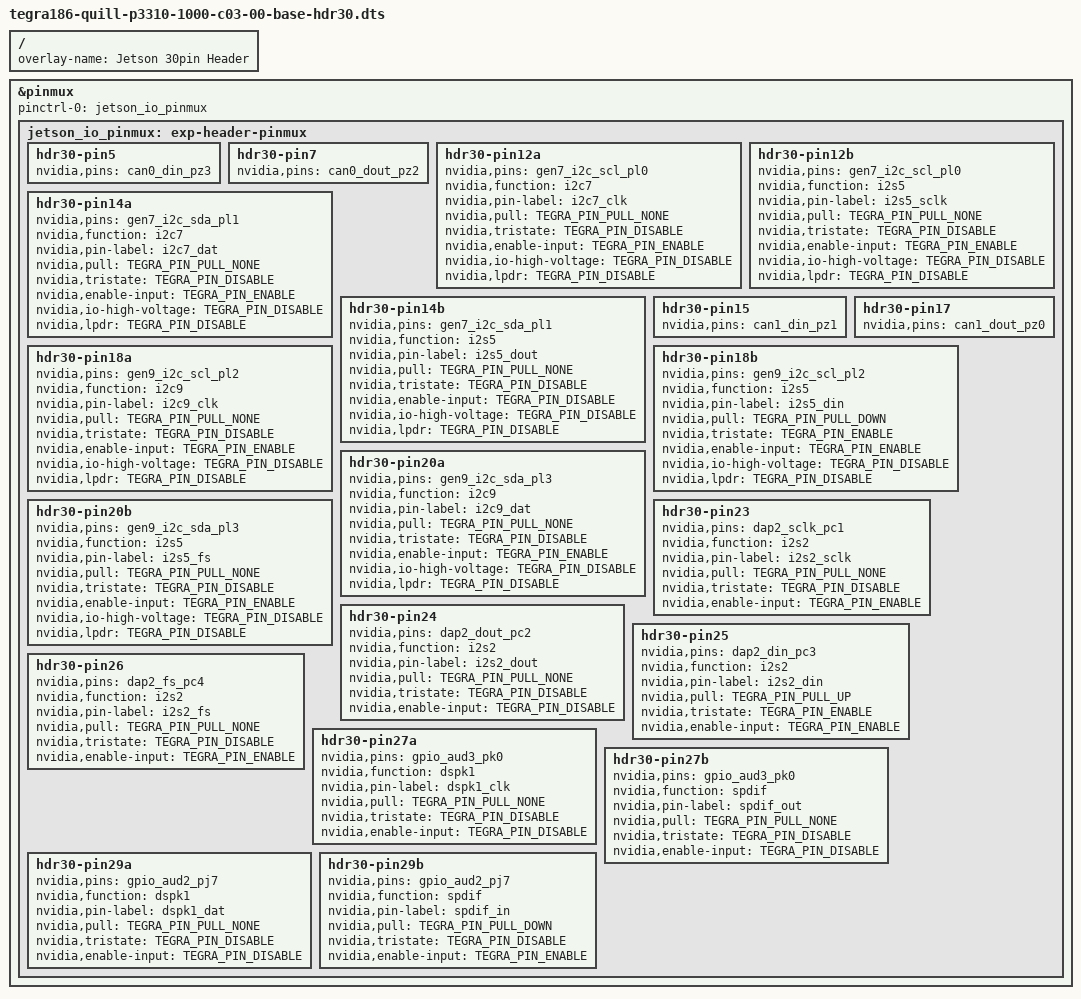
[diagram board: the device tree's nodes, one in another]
/*
 * Copyright (c) 2021, NVIDIA CORPORATION.  All rights reserved.
 *
 * This program is free software; you can redistribute it and/or modify it
 * under the terms and conditions of the GNU General Public License,
 * version 2, as published by the Free Software Foundation.
 *
 * This program is distributed in the hope it will be useful, but WITHOUT
 * ANY WARRANTY; without even the implied warranty of MERCHANTABILITY or
 * FITNESS FOR A PARTICULAR PURPOSE.  See the GNU General Public License for
 * more details.
 *
 * You should have received a copy of the GNU General Public License
 * along with this program.  If not, see <http://www.gnu.org/licenses/>.
 */

/*
 * Device-tree overlay for tegra186-quill-p3310-1000-c03-00-base
 * 30-pin Expansion Header.
 */

/dts-v1/;
/plugin/;

#include <dt-bindings/pinctrl/pinctrl-tegra.h>
#include <dt-common/jetson/tegra186-quill-p3310-1000-c03-00-base.h>

/ {
	overlay-name = "Jetson 30pin Header";
	compatible = JETSON_COMPATIBLE;

	fragment@0 {
		target = <&pinmux>;
		__overlay__ {
			pinctrl-names = "default";
			pinctrl-0 = <&jetson_io_pinmux>;
			jetson_io_pinmux: exp-header-pinmux {
				hdr30-pin5 {
					nvidia,pins = "can0_din_pz3";
				};
				hdr30-pin7 {
					nvidia,pins = "can0_dout_pz2";
				};
				hdr30-pin12a {
					nvidia,pins = "gen7_i2c_scl_pl0";
					nvidia,function = "i2c7";
					nvidia,pin-label = "i2c7_clk";
					nvidia,pull = <TEGRA_PIN_PULL_NONE>;
					nvidia,tristate = <TEGRA_PIN_DISABLE>;
					nvidia,enable-input = <TEGRA_PIN_ENABLE>;
					nvidia,io-high-voltage = <TEGRA_PIN_DISABLE>;
					nvidia,lpdr = <TEGRA_PIN_DISABLE>;
				};
				hdr30-pin12b {
					nvidia,pins = "gen7_i2c_scl_pl0";
					nvidia,function = "i2s5";
					nvidia,pin-label = "i2s5_sclk";
					nvidia,pull = <TEGRA_PIN_PULL_NONE>;
					nvidia,tristate = <TEGRA_PIN_DISABLE>;
					nvidia,enable-input = <TEGRA_PIN_ENABLE>;
					nvidia,io-high-voltage = <TEGRA_PIN_DISABLE>;
					nvidia,lpdr = <TEGRA_PIN_DISABLE>;
				};
				hdr30-pin14a {
					nvidia,pins = "gen7_i2c_sda_pl1";
					nvidia,function = "i2c7";
					nvidia,pin-label = "i2c7_dat";
					nvidia,pull = <TEGRA_PIN_PULL_NONE>;
					nvidia,tristate = <TEGRA_PIN_DISABLE>;
					nvidia,enable-input = <TEGRA_PIN_ENABLE>;
					nvidia,io-high-voltage = <TEGRA_PIN_DISABLE>;
					nvidia,lpdr = <TEGRA_PIN_DISABLE>;
				};
				hdr30-pin14b {
					nvidia,pins = "gen7_i2c_sda_pl1";
					nvidia,function = "i2s5";
					nvidia,pin-label = "i2s5_dout";
					nvidia,pull = <TEGRA_PIN_PULL_NONE>;
					nvidia,tristate = <TEGRA_PIN_DISABLE>;
					nvidia,enable-input = <TEGRA_PIN_DISABLE>;
					nvidia,io-high-voltage = <TEGRA_PIN_DISABLE>;
					nvidia,lpdr = <TEGRA_PIN_DISABLE>;
				};
				hdr30-pin15 {
					nvidia,pins = "can1_din_pz1";
				};
				hdr30-pin17 {
					nvidia,pins = "can1_dout_pz0";
				};
				hdr30-pin18a {
					nvidia,pins = "gen9_i2c_scl_pl2";
					nvidia,function = "i2c9";
					nvidia,pin-label = "i2c9_clk";
					nvidia,pull = <TEGRA_PIN_PULL_NONE>;
					nvidia,tristate = <TEGRA_PIN_DISABLE>;
					nvidia,enable-input = <TEGRA_PIN_ENABLE>;
					nvidia,io-high-voltage = <TEGRA_PIN_DISABLE>;
					nvidia,lpdr = <TEGRA_PIN_DISABLE>;
				};
				hdr30-pin18b {
					nvidia,pins = "gen9_i2c_scl_pl2";
					nvidia,function = "i2s5";
					nvidia,pin-label = "i2s5_din";
					nvidia,pull = <TEGRA_PIN_PULL_DOWN>;
					nvidia,tristate = <TEGRA_PIN_ENABLE>;
					nvidia,enable-input = <TEGRA_PIN_ENABLE>;
					nvidia,io-high-voltage = <TEGRA_PIN_DISABLE>;
					nvidia,lpdr = <TEGRA_PIN_DISABLE>;
				};
				hdr30-pin20a {
					nvidia,pins = "gen9_i2c_sda_pl3";
					nvidia,function = "i2c9";
					nvidia,pin-label = "i2c9_dat";
					nvidia,pull = <TEGRA_PIN_PULL_NONE>;
					nvidia,tristate = <TEGRA_PIN_DISABLE>;
					nvidia,enable-input = <TEGRA_PIN_ENABLE>;
					nvidia,io-high-voltage = <TEGRA_PIN_DISABLE>;
					nvidia,lpdr = <TEGRA_PIN_DISABLE>;
				};
				hdr30-pin20b {
					nvidia,pins = "gen9_i2c_sda_pl3";
					nvidia,function = "i2s5";
					nvidia,pin-label = "i2s5_fs";
					nvidia,pull = <TEGRA_PIN_PULL_NONE>;
					nvidia,tristate = <TEGRA_PIN_DISABLE>;
					nvidia,enable-input = <TEGRA_PIN_ENABLE>;
					nvidia,io-high-voltage = <TEGRA_PIN_DISABLE>;
					nvidia,lpdr = <TEGRA_PIN_DISABLE>;
				};
				hdr30-pin23 {
					nvidia,pins = "dap2_sclk_pc1";
					nvidia,function = "i2s2";
					nvidia,pin-label = "i2s2_sclk";
					nvidia,pull = <TEGRA_PIN_PULL_NONE>;
					nvidia,tristate = <TEGRA_PIN_DISABLE>;
					nvidia,enable-input = <TEGRA_PIN_ENABLE>;
				};
				hdr30-pin24 {
					nvidia,pins = "dap2_dout_pc2";
					nvidia,function = "i2s2";
					nvidia,pin-label = "i2s2_dout";
					nvidia,pull = <TEGRA_PIN_PULL_NONE>;
					nvidia,tristate = <TEGRA_PIN_DISABLE>;
					nvidia,enable-input = <TEGRA_PIN_DISABLE>;
				};
				hdr30-pin25 {
					nvidia,pins = "dap2_din_pc3";
					nvidia,function = "i2s2";
					nvidia,pin-label = "i2s2_din";
					nvidia,pull = <TEGRA_PIN_PULL_UP>;
					nvidia,tristate = <TEGRA_PIN_ENABLE>;
					nvidia,enable-input = <TEGRA_PIN_ENABLE>;
				};
				hdr30-pin26 {
					nvidia,pins = "dap2_fs_pc4";
					nvidia,function = "i2s2";
					nvidia,pin-label = "i2s2_fs";
					nvidia,pull = <TEGRA_PIN_PULL_NONE>;
					nvidia,tristate = <TEGRA_PIN_DISABLE>;
					nvidia,enable-input = <TEGRA_PIN_ENABLE>;
				};
				hdr30-pin27a {
					nvidia,pins = "gpio_aud3_pk0";
					nvidia,function = "dspk1";
					nvidia,pin-label = "dspk1_clk";
					nvidia,pull = <TEGRA_PIN_PULL_NONE>;
					nvidia,tristate = <TEGRA_PIN_DISABLE>;
					nvidia,enable-input = <TEGRA_PIN_DISABLE>;
				};
				hdr30-pin27b {
					nvidia,pins = "gpio_aud3_pk0";
					nvidia,function = "spdif";
					nvidia,pin-label = "spdif_out";
					nvidia,pull = <TEGRA_PIN_PULL_NONE>;
					nvidia,tristate = <TEGRA_PIN_DISABLE>;
					nvidia,enable-input = <TEGRA_PIN_DISABLE>;
				};
				hdr30-pin29a {
					nvidia,pins = "gpio_aud2_pj7";
					nvidia,function = "dspk1";
					nvidia,pin-label = "dspk1_dat";
					nvidia,pull = <TEGRA_PIN_PULL_NONE>;
					nvidia,tristate = <TEGRA_PIN_DISABLE>;
					nvidia,enable-input = <TEGRA_PIN_DISABLE>;
				};
				hdr30-pin29b {
					nvidia,pins = "gpio_aud2_pj7";
					nvidia,function = "spdif";
					nvidia,pin-label = "spdif_in";
					nvidia,pull = <TEGRA_PIN_PULL_DOWN>;
					nvidia,tristate = <TEGRA_PIN_DISABLE>;
					nvidia,enable-input = <TEGRA_PIN_ENABLE>;
				};
			};
		};
	};
};
